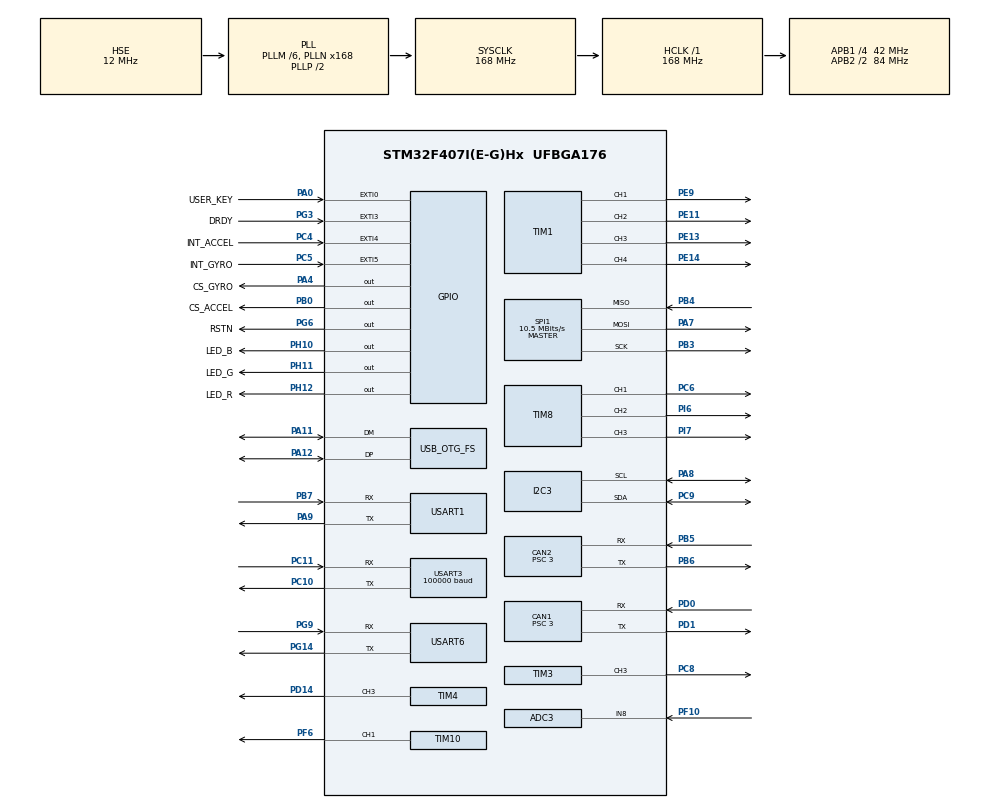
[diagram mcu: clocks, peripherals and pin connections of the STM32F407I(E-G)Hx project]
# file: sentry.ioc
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ADC3.Channel-0\#ChannelRegularConversion=ADC_CHANNEL_8
ADC3.ContinuousConvMode=ENABLE
ADC3.DMAContinuousRequests=ENABLE
ADC3.NbrOfConversionFlag=1
ADC3.Rank-0\#ChannelRegularConversion=1
ADC3.SamplingTime-0\#ChannelRegularConversion=ADC_SAMPLETIME_480CYCLES
CAN1.BS1=CAN_BS1_10TQ
CAN1.BS2=CAN_BS2_3TQ
CAN1.CalculateBaudRate=1000000
CAN1.CalculateTimeBit=1000
CAN1.CalculateTimeQuantum=71.42857142857143
CAN1.NART=ENABLE
CAN1.Prescaler=3
CAN2.BS1=CAN_BS1_10TQ
CAN2.BS2=CAN_BS2_3TQ
CAN2.CalculateBaudRate=1000000
CAN2.CalculateTimeBit=1000
CAN2.CalculateTimeQuantum=71.42857142857143
CAN2.NART=ENABLE
CAN2.Prescaler=3
Dma.ADC3.10.Direction=DMA_PERIPH_TO_MEMORY
Dma.ADC3.10.FIFOMode=DMA_FIFOMODE_DISABLE
Dma.ADC3.10.Instance=DMA2_Stream0
Dma.ADC3.10.MemDataAlignment=DMA_MDATAALIGN_HALFWORD
Dma.ADC3.10.MemInc=DMA_MINC_ENABLE
Dma.ADC3.10.Mode=DMA_NORMAL
Dma.ADC3.10.PeriphDataAlignment=DMA_PDATAALIGN_HALFWORD
Dma.ADC3.10.PeriphInc=DMA_PINC_DISABLE
Dma.ADC3.10.Priority=DMA_PRIORITY_MEDIUM
Dma.I2C3_RX.8.Direction=DMA_PERIPH_TO_MEMORY
Dma.I2C3_RX.8.FIFOMode=DMA_FIFOMODE_DISABLE
Dma.I2C3_RX.8.Instance=DMA1_Stream2
Dma.I2C3_RX.8.MemDataAlignment=DMA_MDATAALIGN_BYTE
Dma.I2C3_RX.8.MemInc=DMA_MINC_ENABLE
Dma.I2C3_RX.8.Mode=DMA_NORMAL
Dma.I2C3_RX.8.PeriphDataAlignment=DMA_PDATAALIGN_BYTE
Dma.I2C3_RX.8.PeriphInc=DMA_PINC_DISABLE
Dma.I2C3_RX.8.Priority=DMA_PRIORITY_HIGH
Dma.I2C3_TX.9.Direction=DMA_MEMORY_TO_PERIPH
Dma.I2C3_TX.9.FIFOMode=DMA_FIFOMODE_DISABLE
Dma.I2C3_TX.9.Instance=DMA1_Stream4
Dma.I2C3_TX.9.MemDataAlignment=DMA_MDATAALIGN_BYTE
Dma.I2C3_TX.9.MemInc=DMA_MINC_ENABLE
Dma.I2C3_TX.9.Mode=DMA_NORMAL
Dma.I2C3_TX.9.PeriphDataAlignment=DMA_PDATAALIGN_BYTE
Dma.I2C3_TX.9.PeriphInc=DMA_PINC_DISABLE
Dma.I2C3_TX.9.Priority=DMA_PRIORITY_LOW
Dma.Request0=USART6_RX
Dma.Request1=USART6_TX
Dma.Request10=ADC3
Dma.Request2=USART1_RX
Dma.Request3=USART1_TX
Dma.Request4=SPI1_RX
Dma.Request5=SPI1_TX
Dma.Request6=TIM4_CH3
Dma.Request7=USART3_RX
Dma.Request8=I2C3_RX
Dma.Request9=I2C3_TX
Dma.SPI1_RX.4.Direction=DMA_PERIPH_TO_MEMORY
Dma.SPI1_RX.4.FIFOMode=DMA_FIFOMODE_DISABLE
Dma.SPI1_RX.4.Instance=DMA2_Stream2
Dma.SPI1_RX.4.MemDataAlignment=DMA_MDATAALIGN_BYTE
Dma.SPI1_RX.4.MemInc=DMA_MINC_ENABLE
Dma.SPI1_RX.4.Mode=DMA_NORMAL
Dma.SPI1_RX.4.PeriphDataAlignment=DMA_PDATAALIGN_BYTE
Dma.SPI1_RX.4.PeriphInc=DMA_PINC_DISABLE
Dma.SPI1_RX.4.Priority=DMA_PRIORITY_VERY_HIGH
Dma.SPI1_TX.5.Direction=DMA_MEMORY_TO_PERIPH
Dma.SPI1_TX.5.FIFOMode=DMA_FIFOMODE_DISABLE
Dma.SPI1_TX.5.Instance=DMA2_Stream3
Dma.SPI1_TX.5.MemDataAlignment=DMA_MDATAALIGN_BYTE
Dma.SPI1_TX.5.MemInc=DMA_MINC_ENABLE
Dma.SPI1_TX.5.Mode=DMA_NORMAL
Dma.SPI1_TX.5.PeriphDataAlignment=DMA_PDATAALIGN_BYTE
Dma.SPI1_TX.5.PeriphInc=DMA_PINC_DISABLE
Dma.SPI1_TX.5.Priority=DMA_PRIORITY_LOW
Dma.TIM4_CH3.6.Direction=DMA_PERIPH_TO_MEMORY
Dma.TIM4_CH3.6.FIFOMode=DMA_FIFOMODE_DISABLE
Dma.TIM4_CH3.6.Instance=DMA1_Stream7
Dma.TIM4_CH3.6.MemDataAlignment=DMA_MDATAALIGN_HALFWORD
Dma.TIM4_CH3.6.MemInc=DMA_MINC_ENABLE
Dma.TIM4_CH3.6.Mode=DMA_NORMAL
Dma.TIM4_CH3.6.PeriphDataAlignment=DMA_PDATAALIGN_HALFWORD
Dma.TIM4_CH3.6.PeriphInc=DMA_PINC_DISABLE
Dma.TIM4_CH3.6.Priority=DMA_PRIORITY_LOW
Dma.USART1_RX.2.Direction=DMA_PERIPH_TO_MEMORY
Dma.USART1_RX.2.FIFOMode=DMA_FIFOMODE_DISABLE
Dma.USART1_RX.2.Instance=DMA2_Stream5
Dma.USART1_RX.2.MemDataAlignment=DMA_MDATAALIGN_BYTE
Dma.USART1_RX.2.MemInc=DMA_MINC_ENABLE
Dma.USART1_RX.2.Mode=DMA_NORMAL
Dma.USART1_RX.2.PeriphDataAlignment=DMA_PDATAALIGN_BYTE
Dma.USART1_RX.2.PeriphInc=DMA_PINC_DISABLE
Dma.USART1_RX.2.Priority=DMA_PRIORITY_HIGH
Dma.USART1_TX.3.Direction=DMA_MEMORY_TO_PERIPH
Dma.USART1_TX.3.FIFOMode=DMA_FIFOMODE_DISABLE
Dma.USART1_TX.3.Instance=DMA2_Stream7
Dma.USART1_TX.3.MemDataAlignment=DMA_MDATAALIGN_BYTE
Dma.USART1_TX.3.MemInc=DMA_MINC_ENABLE
Dma.USART1_TX.3.Mode=DMA_NORMAL
Dma.USART1_TX.3.PeriphDataAlignment=DMA_PDATAALIGN_BYTE
Dma.USART1_TX.3.PeriphInc=DMA_PINC_DISABLE
Dma.USART1_TX.3.Priority=DMA_PRIORITY_HIGH
Dma.USART3_RX.7.Direction=DMA_PERIPH_TO_MEMORY
Dma.USART3_RX.7.FIFOMode=DMA_FIFOMODE_DISABLE
Dma.USART3_RX.7.Instance=DMA1_Stream1
Dma.USART3_RX.7.MemDataAlignment=DMA_MDATAALIGN_BYTE
Dma.USART3_RX.7.MemInc=DMA_MINC_ENABLE
Dma.USART3_RX.7.Mode=DMA_NORMAL
Dma.USART3_RX.7.PeriphDataAlignment=DMA_PDATAALIGN_BYTE
Dma.USART3_RX.7.PeriphInc=DMA_PINC_DISABLE
Dma.USART3_RX.7.Priority=DMA_PRIORITY_VERY_HIGH
Dma.USART6_RX.0.Direction=DMA_PERIPH_TO_MEMORY
Dma.USART6_RX.0.FIFOMode=DMA_FIFOMODE_DISABLE
Dma.USART6_RX.0.Instance=DMA2_Stream1
Dma.USART6_RX.0.MemDataAlignment=DMA_MDATAALIGN_BYTE
Dma.USART6_RX.0.MemInc=DMA_MINC_ENABLE
Dma.USART6_RX.0.Mode=DMA_NORMAL
Dma.USART6_RX.0.PeriphDataAlignment=DMA_PDATAALIGN_BYTE
Dma.USART6_RX.0.PeriphInc=DMA_PINC_DISABLE
Dma.USART6_RX.0.Priority=DMA_PRIORITY_HIGH
Dma.USART6_TX.1.Direction=DMA_MEMORY_TO_PERIPH
Dma.USART6_TX.1.FIFOMode=DMA_FIFOMODE_DISABLE
Dma.USART6_TX.1.Instance=DMA2_Stream6
Dma.USART6_TX.1.MemDataAlignment=DMA_MDATAALIGN_BYTE
Dma.USART6_TX.1.MemInc=DMA_MINC_ENABLE
Dma.USART6_TX.1.Mode=DMA_NORMAL
Dma.USART6_TX.1.PeriphDataAlignment=DMA_PDATAALIGN_BYTE
Dma.USART6_TX.1.PeriphInc=DMA_PINC_DISABLE
Dma.USART6_TX.1.Priority=DMA_PRIORITY_HIGH
FREERTOS.INCLUDE_pcTaskGetTaskName=1
FREERTOS.INCLUDE_vTaskCleanUpResources=1
FREERTOS.Tasks01=initTask,24,128,StartInitTask,Default,NULL,Dynamic,NULL,NULL
FREERTOS.configENABLE_FPU=1
FREERTOS.configRECORD_STACK_HIGH_ADDRESS=1
FREERTOS.configUSE_NEWLIB_REENTRANT=1
FREERTOS.configUSE_TICKLESS_IDLE=1
I2C3.I2C_Mode=I2C_Fast
Mcu.Family=STM32F4
Mcu.Name=STM32F407I(E-G)Hx
Mcu.Package=UFBGA176
NVIC.DMA1_Stream1_IRQn=true\:5\:0\:false\:false\:true\:true\:false\:true\:true
NVIC.DMA1_Stream2_IRQn=true\:5\:0\:false\:false\:true\:true\:false\:true\:true
NVIC.DMA1_Stream4_IRQn=true\:5\:0\:false\:false\:true\:true\:false\:true\:true
NVIC.DMA1_Stream7_IRQn=true\:5\:0\:false\:false\:true\:true\:false\:true\:true
NVIC.DMA2_Stream0_IRQn=true\:5\:0\:false\:false\:true\:true\:false\:true\:true
NVIC.DMA2_Stream1_IRQn=true\:5\:0\:false\:false\:true\:true\:false\:true\:true
NVIC.DMA2_Stream2_IRQn=true\:5\:0\:false\:false\:true\:true\:false\:true\:true
NVIC.DMA2_Stream3_IRQn=true\:5\:0\:false\:false\:true\:true\:false\:true\:true
NVIC.DMA2_Stream5_IRQn=true\:5\:0\:false\:false\:true\:false\:false\:true\:true
NVIC.DMA2_Stream6_IRQn=true\:5\:0\:false\:false\:true\:true\:false\:true\:true
NVIC.DMA2_Stream7_IRQn=true\:5\:0\:false\:false\:true\:true\:false\:true\:true
NVIC.EXTI0_IRQn=true\:5\:0\:false\:false\:true\:false\:true\:true\:true
NVIC.EXTI3_IRQn=true\:5\:0\:false\:false\:true\:false\:true\:true\:true
NVIC.EXTI4_IRQn=true\:5\:0\:false\:false\:true\:false\:true\:true\:true
NVIC.EXTI9_5_IRQn=true\:5\:0\:false\:false\:true\:false\:true\:true\:true
NVIC.OTG_FS_IRQn=true\:5\:0\:false\:false\:true\:true\:false\:true\:true
NVIC.PriorityGroup=NVIC_PRIORITYGROUP_4
NVIC.TIM8_TRG_COM_TIM14_IRQn=true\:5\:0\:false\:false\:true\:false\:false\:true\:true
NVIC.TimeBase=TIM8_TRG_COM_TIM14_IRQn
NVIC.TimeBaseIP=TIM14
NVIC.USART1_IRQn=true\:5\:0\:false\:false\:true\:true\:false\:true\:true
NVIC.USART6_IRQn=true\:5\:0\:false\:false\:true\:true\:false\:true\:true
PA0-WKUP.GPIO_Label=USER_KEY
PA0-WKUP.GPIO_ModeDefaultEXTI=GPIO_MODE_IT_FALLING
PA0-WKUP.GPIO_PuPd=GPIO_PULLUP
PA0-WKUP.Signal=GPXTI0
PA11.Mode=Device_Only
PA11.Signal=USB_OTG_FS_DM
PA12.Mode=Device_Only
PA12.Signal=USB_OTG_FS_DP
PA13.Mode=Serial_Wire
PA13.Signal=SYS_JTMS-SWDIO
PA14.Mode=Serial_Wire
PA14.Signal=SYS_JTCK-SWCLK
PA4.GPIO_Label=CS_GYRO
PA4.GPIO_PuPd=GPIO_PULLUP
PA4.GPIO_Speed=GPIO_SPEED_FREQ_VERY_HIGH
PA4.PinState=GPIO_PIN_SET
PA4.Signal=GPIO_Output
PA7.Mode=Full_Duplex_Master
PA7.Signal=SPI1_MOSI
PA8.Mode=I2C
PA8.Signal=I2C3_SCL
PA9.Mode=Asynchronous
PA9.Signal=USART1_TX
PB0.GPIO_Label=CS_ACCEL
PB0.GPIO_PuPd=GPIO_PULLUP
PB0.GPIO_Speed=GPIO_SPEED_FREQ_VERY_HIGH
PB0.PinState=GPIO_PIN_SET
PB0.Signal=GPIO_Output
PB3.Mode=Full_Duplex_Master
PB3.Signal=SPI1_SCK
PB4.Mode=Full_Duplex_Master
PB4.Signal=SPI1_MISO
PB5.Mode=CAN_Activate
PB5.Signal=CAN2_RX
PB6.Mode=CAN_Activate
PB6.Signal=CAN2_TX
PB7.Mode=Asynchronous
PB7.Signal=USART1_RX
PC10.Mode=Asynchronous
PC10.Signal=USART3_TX
PC11.Mode=Asynchronous
PC11.Signal=USART3_RX
PC4.GPIO_Label=INT_ACCEL
PC4.Signal=GPXTI4
PC5.GPIO_Label=INT_GYRO
PC5.Signal=GPXTI5
PC6.GPIO_Speed=GPIO_SPEED_FREQ_HIGH
PC6.Signal=S_TIM8_CH1
PC8.Signal=S_TIM3_CH3
PC9.Mode=I2C
PC9.Signal=I2C3_SDA
PD0.Mode=CAN_Activate
PD0.Signal=CAN1_RX
PD1.Mode=CAN_Activate
PD1.Signal=CAN1_TX
PD14.GPIO_Speed=GPIO_SPEED_FREQ_HIGH
PD14.Signal=S_TIM4_CH3
PE11.GPIO_Speed=GPIO_SPEED_FREQ_HIGH
PE11.Signal=S_TIM1_CH2
PE13.GPIO_Speed=GPIO_SPEED_FREQ_HIGH
PE13.Signal=S_TIM1_CH3
PE14.GPIO_Speed=GPIO_SPEED_FREQ_HIGH
PE14.Signal=S_TIM1_CH4
PE9.GPIO_Speed=GPIO_SPEED_FREQ_HIGH
PE9.Signal=S_TIM1_CH1
PF10.Mode=IN8
PF10.Signal=ADC3_IN8
PF6.GPIO_Speed=GPIO_SPEED_FREQ_MEDIUM
PF6.Signal=S_TIM10_CH1
PG14.Mode=Asynchronous
PG14.Signal=USART6_TX
PG3.GPIO_Label=DRDY
PG3.GPIO_ModeDefaultEXTI=GPIO_MODE_IT_FALLING
PG3.GPIO_PuPd=GPIO_PULLUP
PG3.Signal=GPXTI3
PG6.GPIO_Label=RSTN
PG6.GPIO_PuPd=GPIO_PULLUP
PG6.GPIO_Speed=GPIO_SPEED_FREQ_MEDIUM
PG6.PinState=GPIO_PIN_SET
PG6.Signal=GPIO_Output
PG9.Mode=Asynchronous
PG9.Signal=USART6_RX
PH0-OSC_IN.Mode=HSE-External-Oscillator
PH0-OSC_IN.Signal=RCC_OSC_IN
PH1-OSC_OUT.Mode=HSE-External-Oscillator
PH1-OSC_OUT.Signal=RCC_OSC_OUT
PH10.GPIO_Label=LED_B
PH10.Signal=GPIO_Output
PH11.GPIO_Label=LED_G
PH11.Signal=GPIO_Output
PH12.GPIO_Label=LED_R
PH12.Signal=GPIO_Output
PI6.GPIO_Speed=GPIO_SPEED_FREQ_HIGH
PI6.Signal=S_TIM8_CH2
PI7.GPIO_Speed=GPIO_SPEED_FREQ_HIGH
PI7.Signal=S_TIM8_CH3
ProjectManager.HeapSize=0x8000
ProjectManager.StackSize=0x8000
ProjectManager.TargetToolchain=Makefile
RCC.48MHZClocksFreq_Value=48000000
RCC.AHBFreq_Value=168000000
RCC.APB1CLKDivider=RCC_HCLK_DIV4
RCC.APB1Freq_Value=42000000
RCC.APB1TimFreq_Value=84000000
RCC.APB2CLKDivider=RCC_HCLK_DIV2
RCC.APB2Freq_Value=84000000
RCC.APB2TimFreq_Value=168000000
RCC.CortexFreq_Value=168000000
RCC.EnbaleCSS=true
RCC.HCLKFreq_Value=168000000
RCC.HSE_VALUE=12000000
RCC.HSI_VALUE=16000000
RCC.LSE_VALUE=32768
RCC.PLLM=6
RCC.PLLN=168
RCC.PLLQ=7
RCC.SYSCLKFreq_VALUE=168000000
RCC.SYSCLKSource=RCC_SYSCLKSOURCE_PLLCLK
RCC.VCOOutputFreq_Value=336000000
SH.S_TIM10_CH1.0=TIM10_CH1,PWM Generation1 CH1
SH.S_TIM1_CH1.0=TIM1_CH1,PWM Generation1 CH1
SH.S_TIM1_CH2.0=TIM1_CH2,PWM Generation2 CH2
SH.S_TIM1_CH3.0=TIM1_CH3,PWM Generation3 CH3
SH.S_TIM1_CH4.0=TIM1_CH4,PWM Generation4 CH4
SH.S_TIM3_CH3.0=TIM3_CH3,PWM Generation3 CH3
SH.S_TIM4_CH3.0=TIM4_CH3,PWM Generation3 CH3
SH.S_TIM8_CH1.0=TIM8_CH1,PWM Generation1 CH1
SH.S_TIM8_CH2.0=TIM8_CH2,PWM Generation2 CH2
SH.S_TIM8_CH3.0=TIM8_CH3,PWM Generation3 CH3
SPI1.BaudRatePrescaler=SPI_BAUDRATEPRESCALER_8
SPI1.CalculateBaudRate=10.5 MBits/s
SPI1.Direction=SPI_DIRECTION_2LINES
SPI1.Mode=SPI_MODE_MASTER
SPI1.VirtualType=VM_MASTER
STMicroelectronics.X-CUBE-ALGOBUILD.1.3.0.LibraryCcDSPOoLibraryJjDSPOoLibrary=true
TIM1.Channel-PWM\ Generation1\ CH1=TIM_CHANNEL_1
TIM1.Channel-PWM\ Generation2\ CH2=TIM_CHANNEL_2
TIM1.Channel-PWM\ Generation3\ CH3=TIM_CHANNEL_3
TIM1.Channel-PWM\ Generation4\ CH4=TIM_CHANNEL_4
TIM10.Channel=TIM_CHANNEL_1
TIM3.Channel-PWM\ Generation3\ CH3=TIM_CHANNEL_3
TIM4.Channel-PWM\ Generation3\ CH3=TIM_CHANNEL_3
TIM8.Channel-PWM\ Generation1\ CH1=TIM_CHANNEL_1
TIM8.Channel-PWM\ Generation2\ CH2=TIM_CHANNEL_2
TIM8.Channel-PWM\ Generation3\ CH3=TIM_CHANNEL_3
USART1.VirtualMode=VM_ASYNC
USART3.BaudRate=100000
USART3.Mode=MODE_RX
USART3.VirtualMode=VM_ASYNC
USART6.VirtualMode=VM_ASYNC
USB_DEVICE.CLASS_NAME_FS=CDC
USB_DEVICE.PID_CDC_FS=12345
USB_DEVICE.PRODUCT_STRING_CDC_FS=Fuzhoushidi Virtual Port Com
USB_DEVICE.VirtualMode-CDC_FS=Cdc
USB_DEVICE.VirtualModeFS=Cdc_FS
USB_OTG_FS.VirtualMode=Device_Only
VP_CRC_VS_CRC.Mode=CRC_Activate
VP_FREERTOS_VS_CMSIS_V2.Mode=CMSIS_V2
VP_RNG_VS_RNG.Mode=RNG_Activate
VP_RTC_VS_RTC_Activate.Mode=RTC_Enabled
VP_STMicroelectronics.X-CUBE-ALGOBUILD_VS_DSPOoLibraryJjLibrary_1.3.0_1.3.0.Mode=DSPOoLibraryJjLibrary
VP_SYS_VS_tim14.Mode=TIM14
VP_TIM10_VS_ClockSourceINT.Mode=Enable_Timer
VP_TIM1_VS_ClockSourceINT.Mode=Internal
VP_TIM3_VS_ClockSourceINT.Mode=Internal
VP_TIM4_VS_ClockSourceINT.Mode=Internal
VP_TIM8_VS_ClockSourceINT.Mode=Internal
VP_USB_DEVICE_VS_USB_DEVICE_CDC_FS.Mode=CDC_FS
board=custom

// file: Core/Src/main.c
/* USER CODE BEGIN Header */
/**
  ******************************************************************************
  * @file           : main.c
  * @brief          : Main program body
  ******************************************************************************
  * @attention
  *
  * Copyright (c) 2024 STMicroelectronics.
  * All rights reserved.
  *
  * This software is licensed under terms that can be found in the LICENSE file
  * in the root directory of this software component.
  * If no LICENSE file comes with this software, it is provided AS-IS.
  *
  ******************************************************************************
  */
/* USER CODE END Header */
#include "main.h"
#include "cmsis_os.h"
#include "adc.h"
#include "can.h"
#include "crc.h"
#include "dma.h"
#include "i2c.h"
#include "rng.h"
#include "rtc.h"
#include "spi.h"
#include "tim.h"
#include "usart.h"
#include "usb_device.h"
#include "gpio.h"

/* USER CODE BEGIN Includes */
#include "__init__.h"
/* USER CODE END Includes */

void SystemClock_Config(void);
void MX_FREERTOS_Init(void);

int main(void)
{

  /* MCU Configuration--------------------------------------------------------*/

  /* Reset of all peripherals, Initializes the Flash interface and the Systick. */
  HAL_Init();

  /* USER CODE BEGIN Init */
  __user_lib_init();
  /* USER CODE END Init */

  /* Configure the system clock */
  SystemClock_Config();

  /* Initialize all configured peripherals */
  MX_GPIO_Init();
  MX_DMA_Init();
  MX_CAN1_Init();
  MX_CAN2_Init();
  MX_CRC_Init();
  MX_RNG_Init();
  MX_USART1_UART_Init();
  MX_USART6_UART_Init();
  MX_SPI1_Init();
  MX_RTC_Init();
  MX_TIM1_Init();
  MX_TIM10_Init();
  MX_ADC3_Init();
  MX_TIM4_Init();
  MX_TIM8_Init();
  MX_USART3_UART_Init();
  MX_I2C3_Init();
  MX_TIM3_Init();

  /* Init scheduler */
  osKernelInitialize();

  /* Call init function for freertos objects (in cmsis_os2.c) */
  MX_FREERTOS_Init();

  /* Start scheduler */
  osKernelStart();

  /* We should never get here as control is now taken by the scheduler */

  /* Infinite loop */
  while (1)
  {

  }
}

void SystemClock_Config(void)
{
  RCC_OscInitTypeDef RCC_OscInitStruct = {0};
  RCC_ClkInitTypeDef RCC_ClkInitStruct = {0};

  /** Configure the main internal regulator output voltage
  */
  __HAL_RCC_PWR_CLK_ENABLE();
  __HAL_PWR_VOLTAGESCALING_CONFIG(PWR_REGULATOR_VOLTAGE_SCALE1);

  /** Initializes the RCC Oscillators according to the specified parameters
  * in the RCC_OscInitTypeDef structure.
  */
  RCC_OscInitStruct.OscillatorType = RCC_OSCILLATORTYPE_LSI|RCC_OSCILLATORTYPE_HSE;
  RCC_OscInitStruct.HSEState = RCC_HSE_ON;
  RCC_OscInitStruct.LSIState = RCC_LSI_ON;
  RCC_OscInitStruct.PLL.PLLState = RCC_PLL_ON;
  RCC_OscInitStruct.PLL.PLLSource = RCC_PLLSOURCE_HSE;
  RCC_OscInitStruct.PLL.PLLM = 6;
  RCC_OscInitStruct.PLL.PLLN = 168;
  RCC_OscInitStruct.PLL.PLLP = RCC_PLLP_DIV2;
  RCC_OscInitStruct.PLL.PLLQ = 7;
  if (HAL_RCC_OscConfig(&RCC_OscInitStruct) != HAL_OK)
  {
    Error_Handler();
  }

  /** Initializes the CPU, AHB and APB buses clocks
  */
  RCC_ClkInitStruct.ClockType = RCC_CLOCKTYPE_HCLK|RCC_CLOCKTYPE_SYSCLK
                              |RCC_CLOCKTYPE_PCLK1|RCC_CLOCKTYPE_PCLK2;
  RCC_ClkInitStruct.SYSCLKSource = RCC_SYSCLKSOURCE_PLLCLK;
  RCC_ClkInitStruct.AHBCLKDivider = RCC_SYSCLK_DIV1;
  RCC_ClkInitStruct.APB1CLKDivider = RCC_HCLK_DIV4;
  RCC_ClkInitStruct.APB2CLKDivider = RCC_HCLK_DIV2;

  if (HAL_RCC_ClockConfig(&RCC_ClkInitStruct, FLASH_LATENCY_5) != HAL_OK)
  {
    Error_Handler();
  }

  /** Enables the Clock Security System
  */
  HAL_RCC_EnableCSS();
}

void HAL_TIM_PeriodElapsedCallback(TIM_HandleTypeDef *htim)
{
  if (htim->Instance == TIM14) {
    HAL_IncTick();
  }
}

void Error_Handler(void)
{
  __disable_irq();
  while (1)
  {
  }
}

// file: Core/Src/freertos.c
/* USER CODE BEGIN Header */
/**
  ******************************************************************************
  * File Name          : freertos.c
  * Description        : Code for freertos applications
  ******************************************************************************
  * @attention
  *
  * Copyright (c) 2024 STMicroelectronics.
  * All rights reserved.
  *
  * This software is licensed under terms that can be found in the LICENSE file
  * in the root directory of this software component.
  * If no LICENSE file comes with this software, it is provided AS-IS.
  *
  ******************************************************************************
  */
/* USER CODE END Header */

#include "FreeRTOS.h"
#include "task.h"
#include "main.h"
#include "cmsis_os.h"

/* Definitions for initTask */
osThreadId_t initTaskHandle;
const osThreadAttr_t initTask_attributes = {
  .name = "initTask",
  .stack_size = 128 * 4,
  .priority = (osPriority_t) osPriorityNormal,
};

void StartInitTask(void *argument);

extern void MX_USB_DEVICE_Init(void);
void MX_FREERTOS_Init(void); /* (MISRA C 2004 rule 8.1) */

/* USER CODE BEGIN PREPOSTSLEEP */
__weak void PreSleepProcessing(uint32_t ulExpectedIdleTime)
{
/* place for user code */
}

__weak void PostSleepProcessing(uint32_t ulExpectedIdleTime)
{
/* place for user code */
}
/* USER CODE END PREPOSTSLEEP */

void MX_FREERTOS_Init(void) {

  /* Create the thread(s) */
  /* creation of initTask */
  initTaskHandle = osThreadNew(StartInitTask, NULL, &initTask_attributes);

}

void StartInitTask(void *argument)
{
  /* init code for USB_DEVICE */
  MX_USB_DEVICE_Init();
  for(;;)
  {
    osDelay(1);
  }
}
